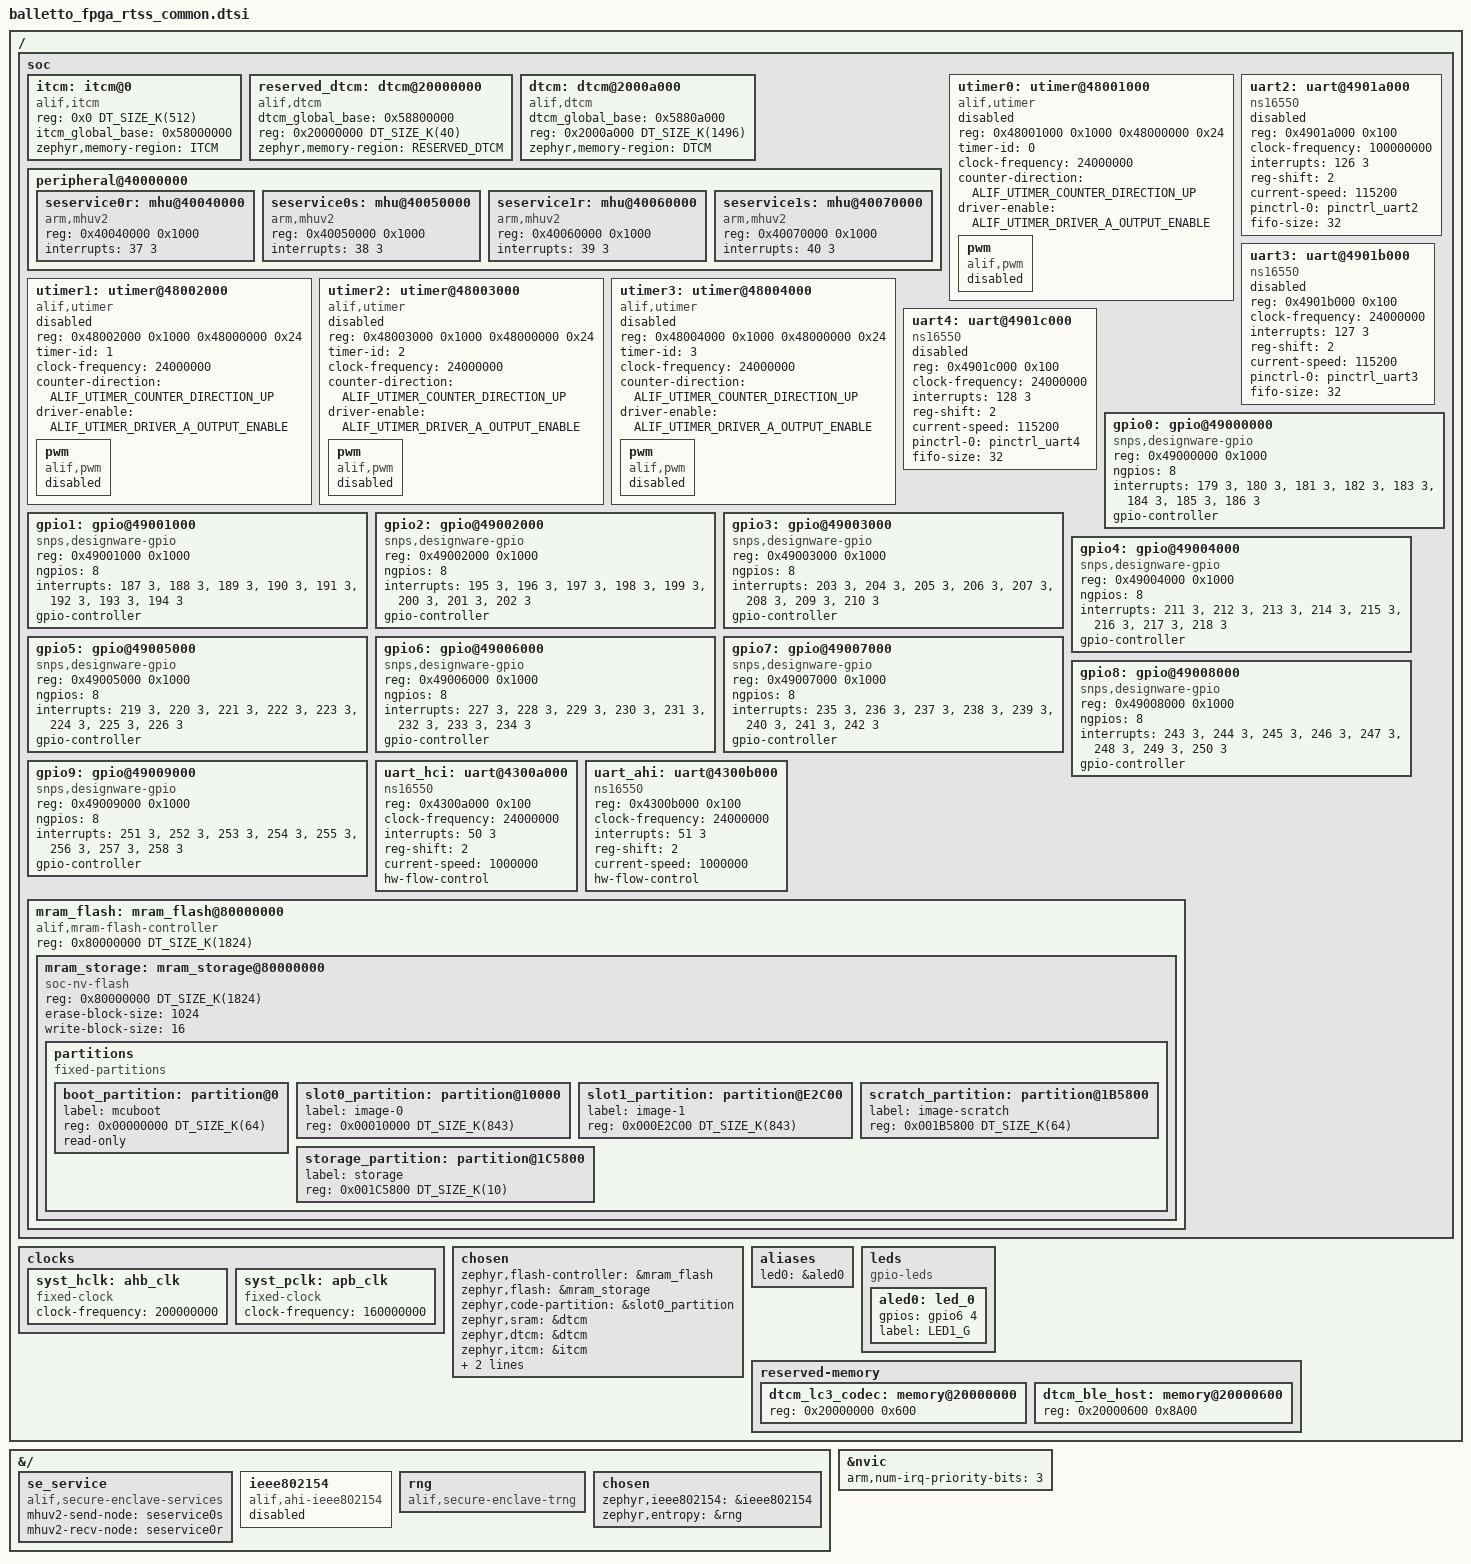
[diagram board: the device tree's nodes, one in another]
/* Copyright (c) 2024 Alif Semiconductor
 *
 * SPDX-License-Identifier: Apache-2.0
 */
#include <arm/armv8.1-m.dtsi>
#include <zephyr/dt-bindings/timer/alif_utimer.h>
#include <zephyr/dt-bindings/pwm/pwm.h>
#include <mem.h>
/ {
	soc {
		itcm: itcm@0 {
			compatible = "alif,itcm", "zephyr,memory-region";
			reg = <0x0 DT_SIZE_K(512)>;
			itcm_global_base = <0x58000000>;
			zephyr,memory-region = "ITCM";
		};

		reserved_dtcm: dtcm@20000000 {
			compatible = "alif,dtcm", "zephyr,memory-region";
			dtcm_global_base = <0x58800000>;
			reg = <0x20000000 DT_SIZE_K(40)>;
			zephyr,memory-region = "RESERVED_DTCM";
		};

		dtcm: dtcm@2000a000 {
			compatible = "alif,dtcm", "zephyr,memory-region";
			dtcm_global_base = <0x5880a000>;
			reg = <0x2000a000 DT_SIZE_K(1496)>;
			zephyr,memory-region = "DTCM";
		};
		peripheral@40000000 {
			#address-cells = < 0x1 >;
			#size-cells = < 0x1 >;
			ranges = < 0x0 0x40000000 0x2000000 >;

			seservice0r: mhu@40040000 {
				compatible = "arm,mhuv2";
				reg = < 0x40040000 0x1000 >;
				interrupts = < 37 3 >;
				interrupt-names = "rx";
			};
			seservice0s: mhu@40050000 {
				compatible = "arm,mhuv2";
				reg = < 0x40050000 0x1000 >;
				interrupts = < 38 3 >;
				interrupt-names = "tx";
			};
			seservice1r: mhu@40060000 {
				compatible = "arm,mhuv2";
				reg = < 0x40060000 0x1000 >;
				interrupts = < 39 3 >;
				interrupt-names = "rx";
			};
			seservice1s: mhu@40070000 {
				compatible = "arm,mhuv2";
				reg = < 0x40070000 0x1000 >;
				interrupts = < 40 3 >;
				interrupt-names = "tx";
			};
		};

		utimer0: utimer@48001000 {
			compatible = "alif,utimer";
			reg = <0x48001000 0x1000 0x48000000 0x24>;
			reg-names = "timer", "global";
			timer-id = <0>;
			clock-frequency = <24000000>;
			counter-direction = < ALIF_UTIMER_COUNTER_DIRECTION_UP >;
			driver-enable = < ALIF_UTIMER_DRIVER_A_OUTPUT_ENABLE >;
			status = "disabled";

			pwm {
				compatible = "alif,pwm";
				#pwm-cells = <3>;
				status = "disabled";
			};
		};

		utimer1: utimer@48002000 {
			compatible = "alif,utimer";
			reg = <0x48002000 0x1000 0x48000000 0x24>;
			reg-names = "timer", "global";
			timer-id = <1>;
			clock-frequency = <24000000>;
			counter-direction = < ALIF_UTIMER_COUNTER_DIRECTION_UP >;
			driver-enable = < ALIF_UTIMER_DRIVER_A_OUTPUT_ENABLE >;
			status = "disabled";

			pwm {
				compatible = "alif,pwm";
				#pwm-cells = <3>;
				status = "disabled";
			};
		};

		utimer2: utimer@48003000 {
			compatible = "alif,utimer";
			reg = <0x48003000 0x1000 0x48000000 0x24>;
			reg-names = "timer", "global";
			timer-id = <2>;
			clock-frequency = <24000000>;
			counter-direction = < ALIF_UTIMER_COUNTER_DIRECTION_UP >;
			driver-enable = < ALIF_UTIMER_DRIVER_A_OUTPUT_ENABLE >;
			status = "disabled";

			pwm {
				compatible = "alif,pwm";
				#pwm-cells = <3>;
				status = "disabled";
			};
		};

		utimer3: utimer@48004000 {
			compatible = "alif,utimer";
			reg = <0x48004000 0x1000 0x48000000 0x24>;
			reg-names = "timer", "global";
			timer-id = <3>;
			clock-frequency = <24000000>;
			counter-direction = < ALIF_UTIMER_COUNTER_DIRECTION_UP >;
			driver-enable = < ALIF_UTIMER_DRIVER_A_OUTPUT_ENABLE >;
			status = "disabled";

			pwm {
				compatible = "alif,pwm";
				#pwm-cells = <3>;
				status = "disabled";
			};
		};

		uart2: uart@4901a000 {
			compatible = "ns16550";
			reg = <0x4901a000 0x100>;
			// 100Mhz baud clock
			clock-frequency = <100000000>;
			interrupts = <126 3>;
			reg-shift = <2>;
			current-speed = <115200>;
			pinctrl-0 = < &pinctrl_uart2 >;
			pinctrl-names = "default";
			fifo-size = <32>;
			status = "disabled";
		};

		uart3: uart@4901b000 {
			compatible = "ns16550";
			reg = <0x4901b000 0x100>;
			/* 24Mhz baud clock */
			clock-frequency = <24000000>;
			interrupts = <127 3>;
			reg-shift = <2>;
			current-speed = <115200>;
			pinctrl-0 = < &pinctrl_uart3 >;
			pinctrl-names = "default";
			fifo-size = <32>;
			status = "disabled";
		};

		uart4: uart@4901c000 {
			compatible = "ns16550";
			reg = <0x4901c000 0x100>;
			/* 24Mhz baud clock */
			clock-frequency = <24000000>;
			interrupts = <128 3>;
			reg-shift = <2>;
			current-speed = <115200>;
			pinctrl-0 = < &pinctrl_uart4 >;
			pinctrl-names = "default";
			fifo-size = <32>;
			status = "disabled";
		};

		gpio0: gpio@49000000 {
			compatible = "snps,designware-gpio";
			reg = <0x49000000 0x1000>;
			ngpios = <8>;
			interrupts =	<179 3>, <180 3>,
					<181 3>, <182 3>,
					<183 3>, <184 3>,
					<185 3>, <186 3>;
			gpio-controller;
			#gpio-cells = <2>;
		};

		gpio1: gpio@49001000 {
			compatible = "snps,designware-gpio";
			reg = <0x49001000 0x1000>;
			ngpios = <8>;
			interrupts =	<187 3>, <188 3>,
					<189 3>, <190 3>,
					<191 3>, <192 3>,
					<193 3>, <194 3>;
			gpio-controller;
			#gpio-cells = <2>;
		};

		gpio2: gpio@49002000 {
			compatible = "snps,designware-gpio";
			reg = <0x49002000 0x1000>;
			ngpios = <8>;
			interrupts =	<195 3>, <196 3>,
					<197 3>, <198 3>,
					<199 3>, <200 3>,
					<201 3>, <202 3>;
			gpio-controller;
			#gpio-cells = <2>;
		};

		gpio3: gpio@49003000 {
			compatible = "snps,designware-gpio";
			reg = <0x49003000 0x1000>;
			ngpios = <8>;
			interrupts =	<203 3>, <204 3>,
					<205 3>, <206 3>,
					<207 3>, <208 3>,
					<209 3>, <210 3>;
			gpio-controller;
			#gpio-cells = <2>;
		};

		gpio4: gpio@49004000 {
			compatible = "snps,designware-gpio";
			reg = <0x49004000 0x1000>;
			ngpios = <8>;
			interrupts =	<211 3>, <212 3>,
					<213 3>, <214 3>,
					<215 3>, <216 3>,
					<217 3>, <218 3>;
			gpio-controller;
			#gpio-cells = <2>;
		};

		gpio5: gpio@49005000 {
			compatible = "snps,designware-gpio";
			reg = <0x49005000 0x1000>;
			ngpios = <8>;
			interrupts =	<219 3>, <220 3>,
					<221 3>, <222 3>,
					<223 3>, <224 3>,
					<225 3>, <226 3>;
			gpio-controller;
			#gpio-cells = <2>;
		};

		gpio6: gpio@49006000 {
			compatible = "snps,designware-gpio";
			reg = <0x49006000 0x1000>;
			ngpios = <8>;
			interrupts =	<227 3>, <228 3>,
					<229 3>, <230 3>,
					<231 3>, <232 3>,
					<233 3>, <234 3>;
			gpio-controller;
			#gpio-cells = <2>;
		};

		gpio7: gpio@49007000 {
			compatible = "snps,designware-gpio";
			reg = <0x49007000 0x1000>;
			ngpios = <8>;
			interrupts =	<235 3>, <236 3>,
					<237 3>, <238 3>,
					<239 3>, <240 3>,
					<241 3>, <242 3>;
			gpio-controller;
			#gpio-cells = <2>;
		};

		gpio8: gpio@49008000 {
			compatible = "snps,designware-gpio";
			reg = <0x49008000 0x1000>;
			ngpios = <8>;
			interrupts =	<243 3>, <244 3>,
					<245 3>, <246 3>,
					<247 3>, <248 3>,
					<249 3>, <250 3>;
			gpio-controller;
			#gpio-cells = <2>;
		};

		gpio9: gpio@49009000 {
			compatible = "snps,designware-gpio";
			reg = <0x49009000 0x1000>;
			ngpios = <8>;
			interrupts =	<251 3>, <252 3>,
					<253 3>, <254 3>,
					<255 3>, <256 3>,
					<257 3>, <258 3>;
			gpio-controller;
			#gpio-cells = <2>;
		};

		uart_hci: uart@4300a000 {
			compatible = "ns16550";
			reg = <0x4300a000 0x100>;
			clock-frequency = <24000000>;
			interrupts = <50 3>;
			reg-shift = <2>;
			current-speed = <1000000>;
			hw-flow-control;
			status = "okay";
		};

		uart_ahi: uart@4300b000 {
			compatible = "ns16550";
			reg = <0x4300b000 0x100>;
			clock-frequency = <24000000>;
			interrupts = <51 3>;
			reg-shift = <2>;
			current-speed = <1000000>;
			hw-flow-control;
			status = "okay";
		};

		mram_flash: mram_flash@80000000 {
			compatible = "alif,mram-flash-controller";
			/* Usable MRAM size for applications is 1824 KB */
			reg = <0x80000000 DT_SIZE_K(1824)>;

			#address-cells = <1>;
			#size-cells = <1>;
			mram_storage: mram_storage@80000000 {
				compatible = "soc-nv-flash";
				reg = <0x80000000 DT_SIZE_K(1824)>;
				erase-block-size = <1024>;
				write-block-size = <16>;
			};
		};
	};

	clocks {
		syst_hclk: ahb_clk {
			compatible = "fixed-clock";
			clock-frequency = <200000000>;
			#clock-cells = <0>;
		};
		syst_pclk: apb_clk {
			compatible = "fixed-clock";
			clock-frequency = <160000000>;
			#clock-cells = <0>;
		};
	};

	chosen {
		zephyr,flash-controller = &mram_flash;
		zephyr,flash = &mram_storage;
		zephyr,code-partition = &slot0_partition;
		zephyr,sram = &dtcm;
		zephyr,dtcm = &dtcm;
		zephyr,itcm = &itcm;
		zephyr,hci-uart = &uart_hci;
		zephyr,ahi-uart = &uart_ahi;
	};

	aliases {
		led0 = &aled0;
	};

	leds {
		compatible = "gpio-leds";
		aled0: led_0 {
			gpios = <&gpio6 4 0>;
			label = "LED1_G";
		};
	};

	reserved-memory {
		#address-cells = <1>;
		#size-cells = <1>;
		ranges;

		/* ROM code for BLE host stack and LC3 codec is compiled to use reserved
		 * static RAM in these defined address ranges. If the ROM code is not used,
		 * these reserved memory regions are ignored and may be used by the
		 * application. But if ROM BLE stack and/or LC3 codec is selected, these
		 * entries are used to create reserved regions in the linker script.
		 */
		dtcm_lc3_codec: memory@20000000 {
			reg = <0x20000000 0x600>;
		};
		dtcm_ble_host: memory@20000600 {
			reg = <0x20000600 0x8A00>;
		};
	};
};

&{/} {
	se_service: se_service {
		compatible = "alif,secure-enclave-services";
		mhuv2-send-node = <&seservice0s>;
		mhuv2-recv-node = <&seservice0r>;
		status = "okay";
	};

	ieee802154: ieee802154 {
		compatible = "alif,ahi-ieee802154";
		status = "disabled";
	};

	rng: rng {
		compatible = "alif,secure-enclave-trng";
		status = "okay";
	};

	chosen {
		zephyr,ieee802154 = &ieee802154;
		zephyr,entropy = &rng;
	};
};

&mram_storage {
	partitions {
		compatible = "fixed-partitions";
		#address-cells = <1>;
		#size-cells = <1>;

		boot_partition: partition@0 {
			label = "mcuboot";
			reg = <0x00000000 DT_SIZE_K(64)>;
			read-only;
		};

		slot0_partition: partition@10000 {
			label = "image-0";
			reg = <0x00010000 DT_SIZE_K(843)>;
		};

		slot1_partition: partition@E2C00 {
			label = "image-1";
			reg = <0x000E2C00 DT_SIZE_K(843)>;
		};

		scratch_partition: partition@1B5800 {
			label = "image-scratch";
			reg = <0x001B5800 DT_SIZE_K(64)>;
		};

		storage_partition: partition@1C5800 {
			label = "storage";
			reg = <0x001C5800 DT_SIZE_K(10)>;
		};
	};
};

&nvic {
	arm,num-irq-priority-bits = <3>;
};
